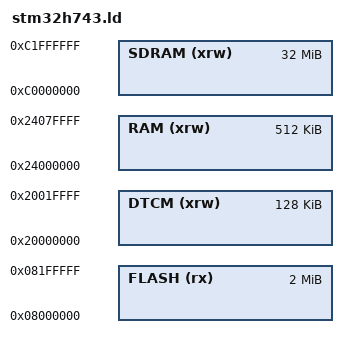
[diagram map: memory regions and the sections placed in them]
MEMORY
{
    FLASH (rx) : ORIGIN = 0x08000000, LENGTH = 2048K
    RAM (xrw)  : ORIGIN = 0x24000000, LENGTH = 512K
    DTCM (xrw) : ORIGIN = 0x20000000, LENGTH = 128K
    SDRAM (xrw): ORIGIN = 0xC0000000, LENGTH = 33554432
}
_estack = ORIGIN(RAM) + LENGTH(RAM);
INCLUDE common.ld
